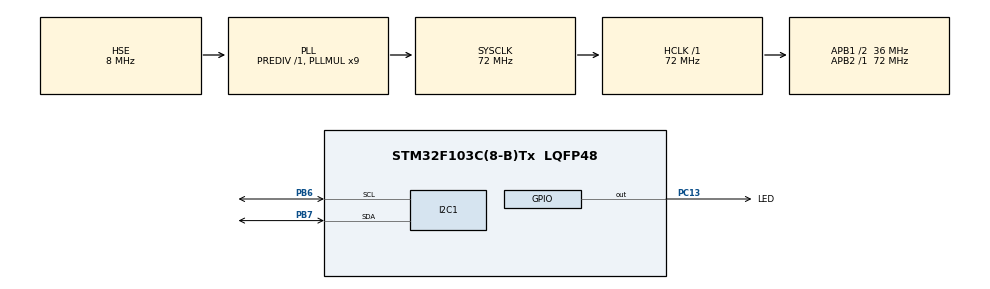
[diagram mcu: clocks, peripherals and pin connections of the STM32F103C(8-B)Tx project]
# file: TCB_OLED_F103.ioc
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I2C1.I2C_Mode=I2C_Fast
Mcu.Family=STM32F1
Mcu.Name=STM32F103C(8-B)Tx
Mcu.Package=LQFP48
NVIC.PriorityGroup=NVIC_PRIORITYGROUP_4
PA13.Mode=Serial_Wire
PA13.Signal=SYS_JTMS-SWDIO
PA14.Mode=Serial_Wire
PA14.Signal=SYS_JTCK-SWCLK
PB6.Mode=I2C
PB6.Signal=I2C1_SCL
PB7.Mode=I2C
PB7.Signal=I2C1_SDA
PC13-TAMPER-RTC.GPIO_Label=LED
PC13-TAMPER-RTC.Signal=GPIO_Output
PD0-OSC_IN.Mode=HSE-External-Oscillator
PD0-OSC_IN.Signal=RCC_OSC_IN
PD1-OSC_OUT.Mode=HSE-External-Oscillator
PD1-OSC_OUT.Signal=RCC_OSC_OUT
ProjectManager.HeapSize=0x200
ProjectManager.StackSize=0x400
ProjectManager.TargetToolchain=STM32CubeIDE
RCC.AHBFreq_Value=72000000
RCC.APB1CLKDivider=RCC_HCLK_DIV2
RCC.APB1Freq_Value=36000000
RCC.APB1TimFreq_Value=72000000
RCC.APB2Freq_Value=72000000
RCC.APB2TimFreq_Value=72000000
RCC.HCLKFreq_Value=72000000
RCC.PLLMUL=RCC_PLL_MUL9
RCC.PLLSourceVirtual=RCC_PLLSOURCE_HSE
RCC.SYSCLKFreq_VALUE=72000000
RCC.SYSCLKSource=RCC_SYSCLKSOURCE_PLLCLK
RCC.USBFreq_Value=72000000
board=custom

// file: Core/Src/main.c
/* USER CODE BEGIN Header */
/**
  ******************************************************************************
  * @file           : main.c
  * @brief          : Main program body
  ******************************************************************************
  * @attention
  *
  * Copyright (c) 2023 STMicroelectronics.
  * All rights reserved.
  *
  * This software is licensed under terms that can be found in the LICENSE file
  * in the root directory of this software component.
  * If no LICENSE file comes with this software, it is provided AS-IS.
  *
  ******************************************************************************
  */
/* USER CODE END Header */
#include "main.h"
#include "oled.h"

 I2C_HandleTypeDef hi2c1;

/* USER CODE BEGIN PV */

 const uint8_t tcb[1024] =
 {
		 0x00, 0x00, 0x00, 0x00, 0x00, 0x00, 0x00, 0x00, 0x00, 0x40, 0xfc, 0xf8, 0xfc, 0xfc, 0xf8, 0xfc,
		 0xf8, 0xfc, 0xfc, 0xf8, 0xfc, 0xfc, 0xf8, 0xfc, 0xf8, 0xfc, 0xfc, 0xf8, 0xfc, 0xfc, 0xf8, 0xfc,
		 0xf8, 0xfc, 0xfc, 0xf8, 0xfc, 0xfc, 0xf8, 0xfc, 0xf8, 0xfc, 0xfc, 0xf8, 0xfc, 0x78, 0x3c, 0x18,
		 0x0c, 0x08, 0x00, 0x80, 0xc0, 0xc0, 0xe0, 0xe0, 0xf0, 0xf0, 0xf0, 0xf8, 0xf8, 0xf8, 0xf8, 0xf8,
		 0xf8, 0xf8, 0xf8, 0xf8, 0xf8, 0xa8, 0x00, 0x00, 0x00, 0xf8, 0xfc, 0x18, 0x1c, 0x18, 0x1c, 0x18,
		 0x1c, 0x18, 0x1c, 0x18, 0x1c, 0x18, 0x0c, 0x18, 0xb8, 0xf8, 0x28, 0x00, 0x00, 0x00, 0xf0, 0xfc,
		 0xf8, 0xfc, 0xf8, 0xf8, 0xf8, 0xf8, 0xf8, 0xf8, 0xf8, 0xf0, 0xf0, 0xe0, 0xe0, 0xc0, 0x80, 0x80,
		 0x00, 0x00, 0x00, 0x00, 0x00, 0x00, 0x00, 0x00, 0x00, 0x00, 0x00, 0x00, 0x00, 0x00, 0x00, 0x00,
		 0x00, 0x00, 0x00, 0x00, 0x00, 0x00, 0x00, 0x00, 0x00, 0x08, 0xff, 0x7f, 0xff, 0x7f, 0x7f, 0xff,
		 0x7f, 0x7f, 0xff, 0x7f, 0x7f, 0xff, 0x7f, 0xff, 0x7f, 0xff, 0xff, 0xff, 0xff, 0xff, 0xff, 0xff,
		 0xff, 0xff, 0xff, 0xff, 0xff, 0xff, 0xff, 0x7f, 0x1f, 0x07, 0x03, 0x81, 0xc0, 0xe0, 0xf8, 0xfc,
		 0xfe, 0xff, 0xff, 0xff, 0xff, 0xff, 0xff, 0xff, 0xff, 0xff, 0xff, 0x7f, 0x7f, 0x7f, 0x3f, 0x3f,
		 0x3f, 0x3f, 0x3f, 0x3f, 0x3f, 0x04, 0x00, 0x00, 0x00, 0xff, 0xff, 0x00, 0x00, 0x00, 0x00, 0x00,
		 0x00, 0x00, 0x00, 0x00, 0x00, 0x00, 0x00, 0x00, 0xfe, 0xaf, 0x00, 0x00, 0x00, 0x1a, 0x1f, 0x1f,
		 0x1f, 0x1f, 0x3f, 0x1f, 0x3f, 0x3f, 0x7f, 0x7f, 0xff, 0xff, 0xff, 0xff, 0xff, 0xff, 0xff, 0xff,
		 0xfe, 0xfc, 0xf0, 0x00, 0x00, 0x00, 0x00, 0x00, 0x00, 0x00, 0x00, 0x00, 0x00, 0x00, 0x00, 0x00,
		 0x00, 0x00, 0x00, 0x00, 0x00, 0x00, 0x00, 0x00, 0x00, 0x00, 0x00, 0x00, 0x00, 0x00, 0x00, 0x00,
		 0x00, 0x00, 0x00, 0x00, 0x00, 0x00, 0x00, 0x00, 0x00, 0xef, 0xff, 0xff, 0xff, 0xff, 0xff, 0xff,
		 0xff, 0xff, 0xff, 0xff, 0x3f, 0x07, 0x01, 0x00, 0xc0, 0xf8, 0xfe, 0xff, 0xff, 0xff, 0xff, 0xff,
		 0xff, 0xff, 0xff, 0x7f, 0x3f, 0x0f, 0x07, 0x03, 0x01, 0x00, 0x00, 0x00, 0x00, 0x00, 0x00, 0x00,
		 0x00, 0x00, 0x00, 0x00, 0x00, 0x00, 0x00, 0x00, 0x00, 0xff, 0xfd, 0x00, 0x00, 0x00, 0x00, 0x00,
		 0x00, 0x00, 0x00, 0x00, 0x00, 0x00, 0x00, 0xda, 0xff, 0x00, 0x00, 0x00, 0x00, 0x00, 0x00, 0x00,
		 0x00, 0x00, 0x00, 0x00, 0x00, 0x00, 0x00, 0x00, 0xe1, 0xff, 0xff, 0xff, 0xff, 0xff, 0xff, 0xff,
		 0xff, 0xff, 0xff, 0x0a, 0x00, 0x00, 0x00, 0x00, 0x00, 0x00, 0x00, 0x00, 0x00, 0x00, 0x00, 0x00,
		 0x00, 0x00, 0x00, 0x00, 0x00, 0x00, 0x00, 0x00, 0x00, 0x00, 0x00, 0x00, 0x00, 0x00, 0x00, 0x00,
		 0x00, 0x00, 0x00, 0x00, 0x00, 0x00, 0x00, 0x00, 0x00, 0xb6, 0xff, 0xff, 0xff, 0xff, 0xff, 0xff,
		 0xff, 0xff, 0xff, 0x17, 0x00, 0x00, 0x00, 0xfa, 0xff, 0xff, 0xff, 0xff, 0xff, 0xff, 0xff, 0xff,
		 0xff, 0xff, 0x03, 0x00, 0x00, 0x00, 0x00, 0x00, 0x00, 0x00, 0x00, 0x00, 0x00, 0x00, 0x00, 0x00,
		 0x00, 0x00, 0x00, 0x00, 0x00, 0x00, 0x00, 0x00, 0x00, 0xbf, 0xff, 0x00, 0x00, 0x00, 0x00, 0x00,
		 0x00, 0x00, 0x00, 0x00, 0x00, 0x00, 0x00, 0xff, 0xaa, 0x00, 0x00, 0x00, 0xfc, 0xfc, 0xfc, 0xfc,
		 0xfc, 0xfc, 0xfc, 0xfc, 0xfe, 0xfe, 0xfe, 0xff, 0xff, 0xff, 0xff, 0xff, 0xff, 0xbf, 0x1f, 0x0f,
		 0x07, 0x03, 0x00, 0x00, 0x00, 0x00, 0x00, 0x00, 0x00, 0x00, 0x00, 0x00, 0x00, 0x00, 0x00, 0x00,
		 0x00, 0x00, 0x00, 0x00, 0x00, 0x00, 0x00, 0x00, 0x00, 0x00, 0x00, 0x00, 0x00, 0x00, 0x00, 0x00,
		 0x00, 0x00, 0x00, 0x00, 0x00, 0x00, 0x00, 0x00, 0x00, 0x6d, 0xff, 0xff, 0xff, 0xff, 0xff, 0xff,
		 0xff, 0xff, 0xff, 0xe4, 0x00, 0x00, 0x00, 0xff, 0xff, 0xff, 0xff, 0xff, 0xff, 0xff, 0xff, 0xff,
		 0xff, 0xff, 0x00, 0x00, 0x00, 0x00, 0x00, 0x00, 0x00, 0x00, 0x00, 0x00, 0x00, 0x00, 0x00, 0x00,
		 0x00, 0x00, 0x00, 0x00, 0x00, 0x00, 0x00, 0x00, 0x00, 0x00, 0x1f, 0xfe, 0xe0, 0x00, 0x00, 0x00,
		 0x00, 0x00, 0x00, 0x00, 0x00, 0x00, 0x29, 0xff, 0x44, 0x00, 0x00, 0x00, 0x0f, 0x0f, 0x0f, 0x0f,
		 0x0f, 0x0f, 0x0f, 0x0f, 0x0f, 0x1f, 0x1f, 0x3f, 0x7f, 0xff, 0xff, 0xff, 0xff, 0xff, 0xff, 0xfe,
		 0xfe, 0xf8, 0xf0, 0xe0, 0x00, 0x00, 0x00, 0x00, 0x00, 0x00, 0x00, 0x00, 0x00, 0x00, 0x00, 0x00,
		 0x00, 0x00, 0x00, 0x00, 0x00, 0x00, 0x00, 0x00, 0x00, 0x00, 0x00, 0x00, 0x00, 0x00, 0x00, 0x00,
		 0x00, 0x00, 0x00, 0x00, 0x00, 0x00, 0x00, 0x00, 0x00, 0xdb, 0xff, 0xff, 0xff, 0xff, 0xff, 0xff,
		 0xff, 0xff, 0xff, 0xff, 0xf0, 0x80, 0x00, 0x00, 0x0f, 0x7f, 0xff, 0xff, 0xff, 0xff, 0xff, 0xff,
		 0xff, 0xff, 0xff, 0xf8, 0xf0, 0xc0, 0x80, 0x00, 0x00, 0x00, 0x00, 0x00, 0x00, 0x00, 0x00, 0x00,
		 0x00, 0x00, 0x00, 0x00, 0x00, 0x00, 0x00, 0x00, 0x00, 0x00, 0x00, 0x00, 0x07, 0x1f, 0x78, 0xe0,
		 0x80, 0x00, 0x00, 0x00, 0x00, 0x00, 0x01, 0xff, 0xea, 0x00, 0x00, 0x00, 0x00, 0x00, 0x00, 0x00,
		 0x00, 0x00, 0x00, 0x00, 0x00, 0x00, 0x00, 0x00, 0x00, 0xc1, 0xff, 0xff, 0xff, 0xff, 0xff, 0xff,
		 0xff, 0xff, 0xff, 0xff, 0xff, 0x00, 0x00, 0x00, 0x00, 0x00, 0x00, 0x00, 0x00, 0x00, 0x00, 0x00,
		 0x00, 0x00, 0x00, 0x00, 0x00, 0x00, 0x00, 0x00, 0x00, 0x00, 0x00, 0x00, 0x00, 0x00, 0x00, 0x00,
		 0x00, 0x00, 0x00, 0x00, 0x00, 0x00, 0x00, 0x00, 0x00, 0xb6, 0xff, 0xff, 0xff, 0xff, 0xff, 0xff,
		 0xff, 0xff, 0xff, 0xff, 0xff, 0xff, 0xfc, 0x50, 0x00, 0x00, 0x03, 0x07, 0x1f, 0x3f, 0x7f, 0xff,
		 0xff, 0xff, 0xff, 0xff, 0xff, 0xff, 0xff, 0xff, 0xfe, 0xfe, 0xfc, 0xf8, 0xf8, 0xf8, 0xf8, 0xf0,
		 0xf8, 0xf0, 0xf8, 0xf0, 0xf8, 0xf8, 0xf8, 0xf8, 0xf8, 0xfc, 0xfc, 0xfc, 0xf8, 0xe0, 0x80, 0x01,
		 0x07, 0x0e, 0x38, 0x70, 0xc0, 0x80, 0x80, 0x57, 0xfd, 0xa0, 0x00, 0x00, 0x00, 0xf8, 0xf8, 0xf8,
		 0xf8, 0xf8, 0xf8, 0xfc, 0xf8, 0xfc, 0xfc, 0xfe, 0xff, 0xff, 0xff, 0xff, 0xff, 0xff, 0xff, 0xff,
		 0xff, 0xff, 0x3f, 0x1f, 0x05, 0x00, 0x00, 0x00, 0x00, 0x00, 0x00, 0x00, 0x00, 0x00, 0x00, 0x00,
		 0x00, 0x00, 0x00, 0x00, 0x00, 0x00, 0x00, 0x00, 0x00, 0x00, 0x00, 0x00, 0x00, 0x00, 0x00, 0x00,
		 0x00, 0x00, 0x00, 0x00, 0x00, 0x00, 0x00, 0x00, 0x00, 0x16, 0x1f, 0x3f, 0x1f, 0x1f, 0x3f, 0x1f,
		 0x1f, 0x3f, 0x1f, 0x1f, 0x3f, 0x1f, 0x1f, 0x15, 0x00, 0x00, 0x00, 0x00, 0x00, 0x00, 0x00, 0x00,
		 0x01, 0x03, 0x03, 0x07, 0x0f, 0x0f, 0x0f, 0x1f, 0x1f, 0x3f, 0x3f, 0x3f, 0x3f, 0x3f, 0x7f, 0x3f,
		 0x7f, 0x3f, 0x7f, 0x3f, 0x7f, 0x3f, 0x3f, 0x3f, 0x3f, 0x3f, 0x3f, 0x1f, 0x1f, 0x1f, 0x0f, 0x0f,
		 0x04, 0x00, 0x00, 0x00, 0x01, 0x01, 0x07, 0x07, 0x0f, 0x1f, 0x10, 0x00, 0x00, 0x00, 0x1f, 0x3f,
		 0x3f, 0x3f, 0x3f, 0x3f, 0x1f, 0x3f, 0x1f, 0x1f, 0x1f, 0x1f, 0x0f, 0x0f, 0x0f, 0x07, 0x03, 0x03,
		 0x01, 0x00, 0x00, 0x00, 0x00, 0x00, 0x00, 0x00, 0x00, 0x00, 0x00, 0x00, 0x00, 0x00, 0x00, 0x00
 };

 const uint8_t tcb_b[1024] =
 {
		 0xff, 0xff, 0xff, 0xff, 0xff, 0xff, 0xff, 0xff, 0xff, 0xbf, 0x03, 0x07, 0x03, 0x03, 0x07, 0x03,
		 0x07, 0x03, 0x03, 0x07, 0x03, 0x03, 0x07, 0x03, 0x07, 0x03, 0x03, 0x07, 0x03, 0x03, 0x07, 0x03,
		 0x07, 0x03, 0x03, 0x07, 0x03, 0x03, 0x07, 0x03, 0x07, 0x03, 0x03, 0x07, 0x03, 0x87, 0xc3, 0xe7,
		 0xf3, 0xf7, 0xff, 0x7f, 0x3f, 0x3f, 0x1f, 0x1f, 0x0f, 0x0f, 0x0f, 0x07, 0x07, 0x07, 0x07, 0x07,
		 0x07, 0x07, 0x07, 0x07, 0x07, 0x57, 0xff, 0xff, 0xff, 0x07, 0x03, 0xe7, 0xe3, 0xe7, 0xe3, 0xe7,
		 0xe3, 0xe7, 0xe3, 0xe7, 0xe3, 0xe7, 0xf3, 0xe7, 0x47, 0x07, 0xd7, 0xff, 0xff, 0xff, 0x0f, 0x03,
		 0x07, 0x03, 0x07, 0x07, 0x07, 0x07, 0x07, 0x07, 0x07, 0x0f, 0x0f, 0x1f, 0x1f, 0x3f, 0x7f, 0x7f,
		 0xff, 0xff, 0xff, 0xff, 0xff, 0xff, 0xff, 0xff, 0xff, 0xff, 0xff, 0xff, 0xff, 0xff, 0xff, 0xff,
		 0xff, 0xff, 0xff, 0xff, 0xff, 0xff, 0xff, 0xff, 0xff, 0xf7, 0x00, 0x80, 0x00, 0x80, 0x80, 0x00,
		 0x80, 0x80, 0x00, 0x80, 0x80, 0x00, 0x80, 0x00, 0x80, 0x00, 0x00, 0x00, 0x00, 0x00, 0x00, 0x00,
		 0x00, 0x00, 0x00, 0x00, 0x00, 0x00, 0x00, 0x80, 0xe0, 0xf8, 0xfc, 0x7e, 0x3f, 0x1f, 0x07, 0x03,
		 0x01, 0x00, 0x00, 0x00, 0x00, 0x00, 0x00, 0x00, 0x00, 0x00, 0x00, 0x80, 0x80, 0x80, 0xc0, 0xc0,
		 0xc0, 0xc0, 0xc0, 0xc0, 0xc0, 0xfb, 0xff, 0xff, 0xff, 0x00, 0x00, 0xff, 0xff, 0xff, 0xff, 0xff,
		 0xff, 0xff, 0xff, 0xff, 0xff, 0xff, 0xff, 0xff, 0x01, 0x50, 0xff, 0xff, 0xff, 0xe5, 0xe0, 0xe0,
		 0xe0, 0xe0, 0xc0, 0xe0, 0xc0, 0xc0, 0x80, 0x80, 0x00, 0x00, 0x00, 0x00, 0x00, 0x00, 0x00, 0x00,
		 0x01, 0x03, 0x0f, 0xff, 0xff, 0xff, 0xff, 0xff, 0xff, 0xff, 0xff, 0xff, 0xff, 0xff, 0xff, 0xff,
		 0xff, 0xff, 0xff, 0xff, 0xff, 0xff, 0xff, 0xff, 0xff, 0xff, 0xff, 0xff, 0xff, 0xff, 0xff, 0xff,
		 0xff, 0xff, 0xff, 0xff, 0xff, 0xff, 0xff, 0xff, 0xff, 0x10, 0x00, 0x00, 0x00, 0x00, 0x00, 0x00,
		 0x00, 0x00, 0x00, 0x00, 0xc0, 0xf8, 0xfe, 0xff, 0x3f, 0x07, 0x01, 0x00, 0x00, 0x00, 0x00, 0x00,
		 0x00, 0x00, 0x00, 0x80, 0xc0, 0xf0, 0xf8, 0xfc, 0xfe, 0xff, 0xff, 0xff, 0xff, 0xff, 0xff, 0xff,
		 0xff, 0xff, 0xff, 0xff, 0xff, 0xff, 0xff, 0xff, 0xff, 0x00, 0x02, 0xff, 0xff, 0xff, 0xff, 0xff,
		 0xff, 0xff, 0xff, 0xff, 0xff, 0xff, 0xff, 0x25, 0x00, 0xff, 0xff, 0xff, 0xff, 0xff, 0xff, 0xff,
		 0xff, 0xff, 0xff, 0xff, 0xff, 0xff, 0xff, 0xff, 0x1e, 0x00, 0x00, 0x00, 0x00, 0x00, 0x00, 0x00,
		 0x00, 0x00, 0x00, 0xf5, 0xff, 0xff, 0xff, 0xff, 0xff, 0xff, 0xff, 0xff, 0xff, 0xff, 0xff, 0xff,
		 0xff, 0xff, 0xff, 0xff, 0xff, 0xff, 0xff, 0xff, 0xff, 0xff, 0xff, 0xff, 0xff, 0xff, 0xff, 0xff,
		 0xff, 0xff, 0xff, 0xff, 0xff, 0xff, 0xff, 0xff, 0xff, 0x49, 0x00, 0x00, 0x00, 0x00, 0x00, 0x00,
		 0x00, 0x00, 0x00, 0xe8, 0xff, 0xff, 0xff, 0x05, 0x00, 0x00, 0x00, 0x00, 0x00, 0x00, 0x00, 0x00,
		 0x00, 0x00, 0xfc, 0xff, 0xff, 0xff, 0xff, 0xff, 0xff, 0xff, 0xff, 0xff, 0xff, 0xff, 0xff, 0xff,
		 0xff, 0xff, 0xff, 0xff, 0xff, 0xff, 0xff, 0xff, 0xff, 0x40, 0x00, 0xff, 0xff, 0xff, 0xff, 0xff,
		 0xff, 0xff, 0xff, 0xff, 0xff, 0xff, 0xff, 0x00, 0x55, 0xff, 0xff, 0xff, 0x03, 0x03, 0x03, 0x03,
		 0x03, 0x03, 0x03, 0x03, 0x01, 0x01, 0x01, 0x00, 0x00, 0x00, 0x00, 0x00, 0x00, 0x40, 0xe0, 0xf0,
		 0xf8, 0xfc, 0xff, 0xff, 0xff, 0xff, 0xff, 0xff, 0xff, 0xff, 0xff, 0xff, 0xff, 0xff, 0xff, 0xff,
		 0xff, 0xff, 0xff, 0xff, 0xff, 0xff, 0xff, 0xff, 0xff, 0xff, 0xff, 0xff, 0xff, 0xff, 0xff, 0xff,
		 0xff, 0xff, 0xff, 0xff, 0xff, 0xff, 0xff, 0xff, 0xff, 0x92, 0x00, 0x00, 0x00, 0x00, 0x00, 0x00,
		 0x00, 0x00, 0x00, 0x1b, 0xff, 0xff, 0xff, 0x00, 0x00, 0x00, 0x00, 0x00, 0x00, 0x00, 0x00, 0x00,
		 0x00, 0x00, 0xff, 0xff, 0xff, 0xff, 0xff, 0xff, 0xff, 0xff, 0xff, 0xff, 0xff, 0xff, 0xff, 0xff,
		 0xff, 0xff, 0xff, 0xff, 0xff, 0xff, 0xff, 0xff, 0xff, 0xff, 0xe0, 0x01, 0x1f, 0xff, 0xff, 0xff,
		 0xff, 0xff, 0xff, 0xff, 0xff, 0xff, 0xd6, 0x00, 0xbb, 0xff, 0xff, 0xff, 0xf0, 0xf0, 0xf0, 0xf0,
		 0xf0, 0xf0, 0xf0, 0xf0, 0xf0, 0xe0, 0xe0, 0xc0, 0x80, 0x00, 0x00, 0x00, 0x00, 0x00, 0x00, 0x01,
		 0x01, 0x07, 0x0f, 0x1f, 0xff, 0xff, 0xff, 0xff, 0xff, 0xff, 0xff, 0xff, 0xff, 0xff, 0xff, 0xff,
		 0xff, 0xff, 0xff, 0xff, 0xff, 0xff, 0xff, 0xff, 0xff, 0xff, 0xff, 0xff, 0xff, 0xff, 0xff, 0xff,
		 0xff, 0xff, 0xff, 0xff, 0xff, 0xff, 0xff, 0xff, 0xff, 0x24, 0x00, 0x00, 0x00, 0x00, 0x00, 0x00,
		 0x00, 0x00, 0x00, 0x00, 0x0f, 0x7f, 0xff, 0xff, 0xf0, 0x80, 0x00, 0x00, 0x00, 0x00, 0x00, 0x00,
		 0x00, 0x00, 0x00, 0x07, 0x0f, 0x3f, 0x7f, 0xff, 0xff, 0xff, 0xff, 0xff, 0xff, 0xff, 0xff, 0xff,
		 0xff, 0xff, 0xff, 0xff, 0xff, 0xff, 0xff, 0xff, 0xff, 0xff, 0xff, 0xff, 0xf8, 0xe1, 0x87, 0x1f,
		 0x7f, 0xff, 0xff, 0xff, 0xff, 0xff, 0xfe, 0x00, 0x15, 0xff, 0xff, 0xff, 0xff, 0xff, 0xff, 0xff,
		 0xff, 0xff, 0xff, 0xff, 0xff, 0xff, 0xff, 0xff, 0xff, 0x3e, 0x00, 0x00, 0x00, 0x00, 0x00, 0x00,
		 0x00, 0x00, 0x00, 0x00, 0x00, 0xff, 0xff, 0xff, 0xff, 0xff, 0xff, 0xff, 0xff, 0xff, 0xff, 0xff,
		 0xff, 0xff, 0xff, 0xff, 0xff, 0xff, 0xff, 0xff, 0xff, 0xff, 0xff, 0xff, 0xff, 0xff, 0xff, 0xff,
		 0xff, 0xff, 0xff, 0xff, 0xff, 0xff, 0xff, 0xff, 0xff, 0x29, 0x00, 0x00, 0x00, 0x00, 0x00, 0x00,
		 0x00, 0x00, 0x00, 0x00, 0x00, 0x00, 0x03, 0x5f, 0xff, 0xff, 0xfc, 0xf8, 0xe0, 0xc0, 0x80, 0x00,
		 0x00, 0x00, 0x00, 0x00, 0x00, 0x00, 0x00, 0x00, 0x01, 0x01, 0x03, 0x07, 0x07, 0x07, 0x07, 0x0f,
		 0x07, 0x0f, 0x07, 0x0f, 0x07, 0x0f, 0x07, 0x07, 0x07, 0x03, 0x03, 0x03, 0x07, 0x1f, 0x7f, 0xfe,
		 0xf8, 0xf1, 0xc7, 0x8f, 0x1f, 0x7f, 0xff, 0x54, 0x00, 0x3f, 0xff, 0xff, 0xff, 0x87, 0x07, 0x07,
		 0x07, 0x07, 0x07, 0x03, 0x07, 0x03, 0x03, 0x01, 0x00, 0x00, 0x00, 0x00, 0x00, 0x00, 0x00, 0x00,
		 0x00, 0x00, 0xc0, 0xe0, 0xfa, 0xff, 0xff, 0xff, 0xff, 0xff, 0xff, 0xff, 0xff, 0xff, 0xff, 0xff,
		 0xff, 0xff, 0xff, 0xff, 0xff, 0xff, 0xff, 0xff, 0xff, 0xff, 0xff, 0xff, 0xff, 0xff, 0xff, 0xff,
		 0xff, 0xff, 0xff, 0xff, 0xff, 0xff, 0xff, 0xff, 0xff, 0xe9, 0xe0, 0xc0, 0xe0, 0xe0, 0xc0, 0xe0,
		 0xe0, 0xc0, 0xe0, 0xe0, 0xc0, 0xe0, 0xe0, 0xe5, 0xff, 0xff, 0xff, 0xff, 0xff, 0xff, 0xff, 0xff,
		 0xfe, 0xfc, 0xfc, 0xf8, 0xf0, 0xf0, 0xf0, 0xe0, 0xe0, 0xc0, 0xc0, 0xc0, 0xc0, 0x80, 0xc0, 0x80,
		 0xc0, 0x80, 0xc0, 0x80, 0xc0, 0x80, 0xc0, 0xc0, 0xc0, 0xc0, 0xc0, 0xe0, 0xe0, 0xe0, 0xf0, 0xf0,
		 0xfb, 0xff, 0xff, 0xff, 0xfe, 0xfe, 0xf8, 0xf8, 0xf0, 0xe0, 0xef, 0xff, 0xff, 0xfe, 0xe0, 0xc0,
		 0xc0, 0xc0, 0xc0, 0xc0, 0xe0, 0xc0, 0xe0, 0xe0, 0xe0, 0xe0, 0xf0, 0xf0, 0xf0, 0xf8, 0xfc, 0xfc,
		 0xfe, 0xff, 0xff, 0xff, 0xff, 0xff, 0xff, 0xff, 0xff, 0xff, 0xff, 0xff, 0xff, 0xff, 0xff, 0xff
 };
/* USER CODE END PV */

void SystemClock_Config(void);
static void MX_GPIO_Init(void);
static void MX_I2C1_Init(void);

int main(void)
{

  /* MCU Configuration--------------------------------------------------------*/

  /* Reset of all peripherals, Initializes the Flash interface and the Systick. */
  HAL_Init();

  /* Configure the system clock */
  SystemClock_Config();

  /* Initialize all configured peripherals */
  MX_GPIO_Init();
  MX_I2C1_Init();
  /* USER CODE BEGIN 2 */
  Oled_Inicializa(&hi2c1);
  Oled_Dibuja(&hi2c1, tcb);
  HAL_Delay(2000);

  /* USER CODE END 2 */

  /* Infinite loop */
  while (1)
  {

    /* USER CODE BEGIN 3 */
	  Oled_LimpiaDisplay(&hi2c1);
	  Oled_EnviaCadenaXY(&hi2c1, "TECNOLOGIA", 0, 0);
	  Oled_EnviaCadenaXY(&hi2c1, "COLMILLO", 1, 0);
	  Oled_EnviaCadenaXY(&hi2c1, "BLANCO", 2, 0);
	  Oled_EnviaCadenaXY(&hi2c1, "Web -> http://", 3, 1);
	  Oled_EnviaCadenaXY(&hi2c1, "colmilloblanco", 4, 1);
	  Oled_EnviaCadenaXY(&hi2c1, ".tech", 5, 5);
	  Oled_EnviaCadenaXY(&hi2c1, "(26/11/2023)", 7, 0);
	  Oled_MuestraPantalla(&hi2c1);

	  HAL_Delay(2000);

	  Oled_LimpiaDisplay(&hi2c1);
	  Oled_EnviaCadenaXY(&hi2c1, "TECNOLOGIA", 3, 3);
	  Oled_EnviaCadenaXY(&hi2c1, "COLMILLO", 4, 4);
	  Oled_EnviaCadenaXY(&hi2c1, "BLANCO", 5, 5);
	  Oled_MuestraPantalla(&hi2c1);
	  HAL_Delay(2000);

	  Oled_Dibuja(&hi2c1, tcb_b);
	  HAL_Delay(2000);

  }
  /* USER CODE END 3 */
}

void SystemClock_Config(void)
{
  RCC_OscInitTypeDef RCC_OscInitStruct = {0};
  RCC_ClkInitTypeDef RCC_ClkInitStruct = {0};

  /** Initializes the RCC Oscillators according to the specified parameters
  * in the RCC_OscInitTypeDef structure.
  */
  RCC_OscInitStruct.OscillatorType = RCC_OSCILLATORTYPE_HSE;
  RCC_OscInitStruct.HSEState = RCC_HSE_ON;
  RCC_OscInitStruct.HSEPredivValue = RCC_HSE_PREDIV_DIV1;
  RCC_OscInitStruct.HSIState = RCC_HSI_ON;
  RCC_OscInitStruct.PLL.PLLState = RCC_PLL_ON;
  RCC_OscInitStruct.PLL.PLLSource = RCC_PLLSOURCE_HSE;
  RCC_OscInitStruct.PLL.PLLMUL = RCC_PLL_MUL9;
  if (HAL_RCC_OscConfig(&RCC_OscInitStruct) != HAL_OK)
  {
    Error_Handler();
  }

  /** Initializes the CPU, AHB and APB buses clocks
  */
  RCC_ClkInitStruct.ClockType = RCC_CLOCKTYPE_HCLK|RCC_CLOCKTYPE_SYSCLK
                              |RCC_CLOCKTYPE_PCLK1|RCC_CLOCKTYPE_PCLK2;
  RCC_ClkInitStruct.SYSCLKSource = RCC_SYSCLKSOURCE_PLLCLK;
  RCC_ClkInitStruct.AHBCLKDivider = RCC_SYSCLK_DIV1;
  RCC_ClkInitStruct.APB1CLKDivider = RCC_HCLK_DIV2;
  RCC_ClkInitStruct.APB2CLKDivider = RCC_HCLK_DIV1;

  if (HAL_RCC_ClockConfig(&RCC_ClkInitStruct, FLASH_LATENCY_2) != HAL_OK)
  {
    Error_Handler();
  }
}

static void MX_I2C1_Init(void)
{

  hi2c1.Instance = I2C1;
  hi2c1.Init.ClockSpeed = 400000;
  hi2c1.Init.DutyCycle = I2C_DUTYCYCLE_2;
  hi2c1.Init.OwnAddress1 = 0;
  hi2c1.Init.AddressingMode = I2C_ADDRESSINGMODE_7BIT;
  hi2c1.Init.DualAddressMode = I2C_DUALADDRESS_DISABLE;
  hi2c1.Init.OwnAddress2 = 0;
  hi2c1.Init.GeneralCallMode = I2C_GENERALCALL_DISABLE;
  hi2c1.Init.NoStretchMode = I2C_NOSTRETCH_DISABLE;
  if (HAL_I2C_Init(&hi2c1) != HAL_OK)
  {
    Error_Handler();
  }

}

static void MX_GPIO_Init(void)
{
  GPIO_InitTypeDef GPIO_InitStruct = {0};

  /* GPIO Ports Clock Enable */
  __HAL_RCC_GPIOC_CLK_ENABLE();
  __HAL_RCC_GPIOD_CLK_ENABLE();
  __HAL_RCC_GPIOA_CLK_ENABLE();
  __HAL_RCC_GPIOB_CLK_ENABLE();

  /*Configure GPIO pin Output Level */
  HAL_GPIO_WritePin(LED_GPIO_Port, LED_Pin, GPIO_PIN_RESET);

  /*Configure GPIO pin : LED_Pin */
  GPIO_InitStruct.Pin = LED_Pin;
  GPIO_InitStruct.Mode = GPIO_MODE_OUTPUT_PP;
  GPIO_InitStruct.Pull = GPIO_NOPULL;
  GPIO_InitStruct.Speed = GPIO_SPEED_FREQ_LOW;
  HAL_GPIO_Init(LED_GPIO_Port, &GPIO_InitStruct);

}

void Error_Handler(void)
{
  __disable_irq();
  while (1)
  {
  }
}
